# MAX32550 register map
Vendor: Maxim Integrated; File version: 1.0
Registers are 32-bit, read-write, reset 0x0 unless marked. A register's access mark holds for its fields unless they carry their own. Offsets are from the block's base; [hi:lo] are bit positions; {n}, {i} and the like mark numbered series.

## ADC — Analog to Digital Converter
Base 0x40034000; register names take the prefix ADC_
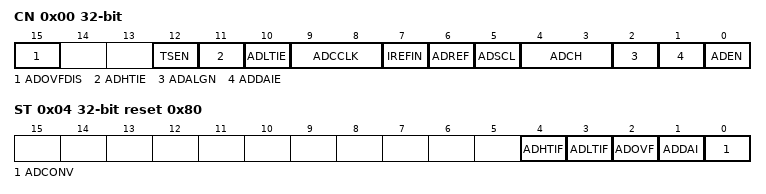
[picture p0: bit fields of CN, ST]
0x00 CN — ADC Control Register
  [15] ADOVFDIS — Overflow Disable
    0=enable (ADST.ADOVF bit will be set when the ADC overflows. In this case ADDATA will return a data of 0x3FF if an overflow occurs.); 1=disable (ADST.ADOVF bit will not be set when an overflow occurs. In this case ADDATA will return the overflowed data.)
  [12] TSEN — Temp Sensor Enable. This bit enables the internal temp sensor available when ADC_CN.ADCH = b11.
    0=disable; 1=enable
  [11] ADHTIE — ADC High Threshold Interrupt Enable
    0=disable; 1=enable
  [10] ADLTIE — ADC Low Threshold Interrupt Enable
    0=disable; 1=enable
  [9:8] ADCCLK — ADC Clock Divider. These bits select the ADC conversion clock in relationship to the APB Clock. The APB is first passed through a divide by 16 prescaler and passed to programmable divider so that ADC clock would be in the range of 8MHz with APB clock frequency of 100MHz.
    0=div16 (PCLK / 16); 1=div32 (PCLK / 32); 2=div64 (PCLK / 64); 3=div128 (PCLK / 128)
  [7] IREFIN ro — Internal Reference Enable. This bit has the same value as ADREF. This bit is read only.
    0=avdd; 1=Internal Reference
  [6] ADREF — ADC Reference Select. This bit selects the reference voltage used in the ADC conversion.
    0=avdd; 1=Internal Reference
  [5] ADSCL — ADC Input Scale. This bit selects the scale factor applies to AN0 and AN1 inputs when using the internal reference. Note that the ADSCL setting is ignored when AVDD is selected as the reference. Note that the ADSCL setting is ignored when AVDD is selected as the reference. ADC Input Scale. This bit selects the scale factor applies to AN0 and AN1 inputs when using the internal reference. Note that the ADSCL setting is ignored when AVDD is selected as the reference. ADC Input Scale. This bit enabled the 1/3 scale factor applied to AN0 and AN1 inputs when using the internal reference. Note that the ADSCL setting is ignored when AVDD is selected as the reference.
    0=disable; 1=enable
  [4:3] ADCH — ADC Input Channel Select. These bits select the input channel to the ADC converter.
    0=an0; 1=an1; 3=tempSensor (Internal Temp Sensor)
  [2] ADALGN — ADC Data Alignment Select. This bit selects the ADC data alignment mode.
    0=rightAlign (ADC data is in right alignment format in ADDDATA[9:0] while ADDATA[15:10] is filled with zero.); 1=leftAlign (ADC data is in left alignment format in ADDDATA[15:6] while ADDATA[5:0] is filled with zero.)
  [1] ADDAIE — ADC Data Available Interrupt Enable
    0=disable; 1=enable
  [0] ADEN — ADC Enable
    0=disable; 1=enable
0x04 ST reset 0x80 — ADC Status Register
  [4] ADHTIF — ADC High Threshold Interrupt Flag. Setting this bit to 1 by software will generate an interrupt if enabled.
    0=inactive; 1=pending (Flag asserted)
  [3] ADLTIF — ADC Low Threshold Interrupt Flag. Setting this bit to 1 by software will generate an interrupt if enabled.
  [2] ADOVF — ADC Overflow Flag. Once set this bit will remain set unless cleared by software.
    0=inactive; 1=pending (Flag asserted)
  [1] ADDAI — ADC Data Available Interrupt Flag
    0=inactive; 1=pending (Flag asserted)
  [0] ADCONV — ADC Start Conversion. Note that since this bit is not cleared on entry to STOP mode, it is up to the user software to clear ADCONV before entering STOP mode. If this bit is not cleared, the ADC will be held in its current state during STOP mode, and will resume operation at the point where it left off when STOP mode is exited. To avoid undesirable current draw by this block it is recommended to clear this bit prior to entering the STOP mode.
    0=Stop ADC conversion. The ADC will stop acquiring data immediately.; 1=Starts an ADC conversion when the ADC is enabled (ADEN=1)
0x08 DATA 16-bit ro — ADC Data Register. When read, this register returns the ADC conversion data. The ADC conversion result will be aligned according to the ADALGN setting.
{0xC+4i} LT{i} (i=0..2) 10-bit — ADC channel Low Threshold Value. When an ADC conversion result of channel is less than ADC Low Threshold value (ADLT), ADLTIF flag will be set.
{0x18+4i} HT{i} (i=0..2) 10-bit — ADC channel High Threshold Value. When an ADC conversion result of channel is greater than ADC High Threshold value (ADHT), ADHTIF flag will be set.
